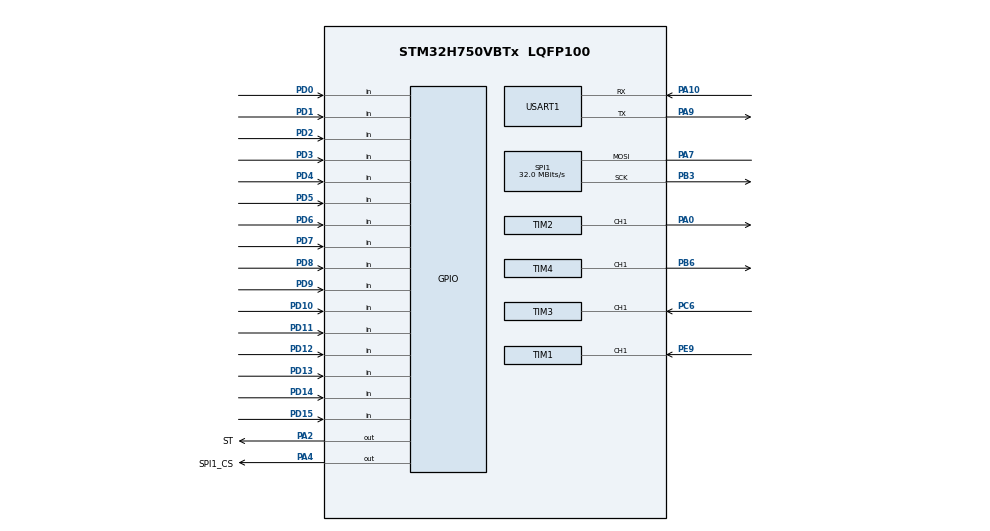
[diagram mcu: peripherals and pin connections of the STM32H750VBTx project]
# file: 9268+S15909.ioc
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CORTEX_M7.CPU_DCache=Disabled
CORTEX_M7.CPU_ICache=Disabled
CORTEX_M7.default_mode_Activation=0
Dma.Request0=USART1_TX
Dma.USART1_TX.0.Direction=DMA_MEMORY_TO_PERIPH
Dma.USART1_TX.0.EventEnable=DISABLE
Dma.USART1_TX.0.FIFOMode=DMA_FIFOMODE_DISABLE
Dma.USART1_TX.0.Instance=DMA1_Stream0
Dma.USART1_TX.0.MemDataAlignment=DMA_MDATAALIGN_BYTE
Dma.USART1_TX.0.MemInc=DMA_MINC_ENABLE
Dma.USART1_TX.0.Mode=DMA_NORMAL
Dma.USART1_TX.0.PeriphDataAlignment=DMA_PDATAALIGN_BYTE
Dma.USART1_TX.0.PeriphInc=DMA_PINC_DISABLE
Dma.USART1_TX.0.Polarity=HAL_DMAMUX_REQ_GEN_RISING
Dma.USART1_TX.0.Priority=DMA_PRIORITY_MEDIUM
Dma.USART1_TX.0.RequestNumber=1
Dma.USART1_TX.0.SignalID=NONE
Dma.USART1_TX.0.SyncEnable=DISABLE
Dma.USART1_TX.0.SyncPolarity=HAL_DMAMUX_SYNC_NO_EVENT
Dma.USART1_TX.0.SyncRequestNumber=1
Dma.USART1_TX.0.SyncSignalID=NONE
Mcu.Family=STM32H7
Mcu.Name=STM32H750VBTx
Mcu.Package=LQFP100
NVIC.DMA1_Stream0_IRQn=true\:0\:0\:false\:false\:true\:false\:true\:true
NVIC.PriorityGroup=NVIC_PRIORITYGROUP_4
NVIC.TIM1_CC_IRQn=true\:0\:0\:false\:false\:true\:true\:true\:true
NVIC.TIM1_TRG_COM_IRQn=true\:0\:0\:false\:false\:true\:true\:true\:true
NVIC.TIM3_IRQn=true\:0\:0\:false\:false\:true\:true\:true\:true
NVIC.USART1_IRQn=true\:0\:0\:false\:false\:true\:true\:true\:true
PA0.Signal=S_TIM2_CH1_ETR
PA10.GPIO_Speed=GPIO_SPEED_FREQ_HIGH
PA10.Mode=Asynchronous
PA10.Signal=USART1_RX
PA2.GPIO_Label=ST
PA2.GPIO_Speed=GPIO_SPEED_FREQ_HIGH
PA2.Signal=GPIO_Output
PA4.GPIO_Label=SPI1_CS
PA4.GPIO_Speed=GPIO_SPEED_FREQ_VERY_HIGH
PA4.Signal=GPIO_Output
PA7.Mode=Simplex_Bidirectional_Master
PA7.Signal=SPI1_MOSI
PA9.GPIO_Speed=GPIO_SPEED_FREQ_HIGH
PA9.Mode=Asynchronous
PA9.Signal=USART1_TX
PB3\ (JTDO/TRACESWO).Mode=Simplex_Bidirectional_Master
PB3\ (JTDO/TRACESWO).Signal=SPI1_SCK
PB6.Signal=S_TIM4_CH1
PC6.Signal=S_TIM3_CH1
PD0.Signal=GPIO_Input
PD1.Signal=GPIO_Input
PD10.Signal=GPIO_Input
PD11.Signal=GPIO_Input
PD12.Signal=GPIO_Input
PD13.Signal=GPIO_Input
PD14.Signal=GPIO_Input
PD15.Signal=GPIO_Input
PD2.Signal=GPIO_Input
PD3.Signal=GPIO_Input
PD4.Signal=GPIO_Input
PD5.Signal=GPIO_Input
PD6.Signal=GPIO_Input
PD7.Signal=GPIO_Input
PD8.Signal=GPIO_Input
PD9.Signal=GPIO_Input
PE9.Signal=S_TIM1_CH1
PH0-OSC_IN\ (PH0).Mode=HSE-External-Oscillator
PH0-OSC_IN\ (PH0).Signal=RCC_OSC_IN
PH1-OSC_OUT\ (PH1).Mode=HSE-External-Oscillator
PH1-OSC_OUT\ (PH1).Signal=RCC_OSC_OUT
ProjectManager.HeapSize=0x400
ProjectManager.StackSize=0x400
ProjectManager.TargetToolchain=STM32CubeIDE
RCC.ADCFreq_Value=16125000
RCC.APB1Freq_Value=120000000
RCC.APB2Freq_Value=120000000
RCC.APB3Freq_Value=120000000
RCC.APB4Freq_Value=120000000
RCC.CortexFreq_Value=480000000
RCC.D1PPRE=RCC_APB3_DIV2
RCC.D2PPRE1=RCC_APB1_DIV2
RCC.D2PPRE2=RCC_APB2_DIV2
RCC.D3PPRE=RCC_APB4_DIV2
RCC.DIVM1=2
RCC.DIVN1=240
RCC.HCLKFreq_Value=240000000
RCC.HPRE=RCC_HCLK_DIV2
RCC.HSE_VALUE=8000000
RCC.PLLSourceVirtual=RCC_PLLSOURCE_HSE
RCC.PWR_Regulator_Voltage_Scale=PWR_REGULATOR_VOLTAGE_SCALE0
RCC.ProductRev=revV
RCC.SPI123CLockSelection=RCC_SPI123CLKSOURCE_CLKP
RCC.SYSCLKFreq_VALUE=480000000
RCC.SYSCLKSource=RCC_SYSCLKSOURCE_PLLCLK
RCC.USBFreq_Value=480000000
SH.S_TIM1_CH1.0=TIM1_CH1,TriggerSource_TI1FP1
SH.S_TIM1_CH1.1=TIM1_CH1,Input_Capture1_from_TI1
SH.S_TIM2_CH1_ETR.0=TIM2_CH1,PWM Generation1 CH1
SH.S_TIM3_CH1.0=TIM3_CH1,Input_Capture1_from_TI1
SH.S_TIM3_CH1.1=TIM3_CH1,TriggerSource_TI1FP1
SH.S_TIM4_CH1.0=TIM4_CH1,PWM Generation1 CH1
SPI1.BaudRatePrescaler=SPI_BAUDRATEPRESCALER_2
SPI1.CalculateBaudRate=32.0 MBits/s
SPI1.DataSize=SPI_DATASIZE_8BIT
SPI1.Direction=SPI_DIRECTION_1LINE
SPI1.Mode=SPI_MODE_MASTER
SPI1.VirtualType=VM_MASTER
TIM1.Channel-Input_Capture1_from_TI1=TIM_CHANNEL_1
TIM1.Prescaler=24-1
TIM2.Channel-PWM\ Generation1\ CH1=TIM_CHANNEL_1
TIM2.Period=100-1
TIM2.Prescaler=10-1
TIM2.Pulse-PWM\ Generation1\ CH1=50
TIM3.Channel-Input_Capture1_from_TI1=TIM_CHANNEL_1
TIM3.Prescaler=10-1
TIM4.Channel-PWM\ Generation1\ CH1=TIM_CHANNEL_1
TIM4.Period=2-1
TIM4.Prescaler=3-1
TIM4.Pulse-PWM\ Generation1\ CH1=1
USART1.VirtualMode-Asynchronous=VM_ASYNC
VP_TIM1_VS_ControllerModeReset.Mode=Reset Mode
VP_TIM3_VS_ControllerModeReset.Mode=Reset Mode
board=custom

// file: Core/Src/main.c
/* USER CODE BEGIN Header */
/**
  ******************************************************************************
  * @file           : main.c
  * @brief          : Main program body
  ******************************************************************************
  * @attention
  *
  * Copyright (c) 2024 STMicroelectronics.
  * All rights reserved.
  *
  * This software is licensed under terms that can be found in the LICENSE file
  * in the root directory of this software component.
  * If no LICENSE file comes with this software, it is provided AS-IS.
  *
  ******************************************************************************
  */
/* USER CODE END Header */
#include "main.h"
#include "dma.h"
#include "spi.h"
#include "tim.h"
#include "usart.h"
#include "gpio.h"

/* USER CODE BEGIN Includes */
#include "Retarget.h"
#include "AD9268.h"
#include <string.h>
/* USER CODE END Includes */

void SystemClock_Config(void);
void PeriphCommonClock_Config(void);

int main(void)
{

  /* MCU Configuration--------------------------------------------------------*/

  /* Reset of all peripherals, Initializes the Flash interface and the Systick. */
  HAL_Init();

  /* Configure the system clock */
  SystemClock_Config();

/* Configure the peripherals common clocks */
  PeriphCommonClock_Config();

  /* Initialize all configured peripherals */
  MX_GPIO_Init();
  MX_DMA_Init();
  MX_TIM1_Init();
  MX_TIM2_Init();
  MX_TIM3_Init();
  MX_TIM4_Init();
  MX_SPI1_Init();
  MX_USART1_UART_Init();
  /* USER CODE BEGIN 2 */
    RetargetInit(&huart1);
    HAL_TIM_PWM_Start(&htim2,TIM_CHANNEL_1);
    HAL_TIM_PWM_Start(&htim4,TIM_CHANNEL_1);
    Init_AD9268();
  /* USER CODE END 2 */

  /* Infinite loop */
  while (1)
  {

    /* USER CODE BEGIN 3 */
//    for(int i=0;i<512;i++)
//    {
//        adc_16bit_value[i] = GPIOD->IDR;
//    }
//      memcpy(adc_ans,adc_16bit_value,1024);
//      HAL_UART_Transmit_DMA(&huart1,adc_ans,1024);
      //printf("%d\r\n",adc_16bit_value);
      DMA_Send();
      //printf("h\r\n");

  }
  /* USER CODE END 3 */
}

void SystemClock_Config(void)
{
  RCC_OscInitTypeDef RCC_OscInitStruct = {0};
  RCC_ClkInitTypeDef RCC_ClkInitStruct = {0};

  /** Supply configuration update enable
  */
  HAL_PWREx_ConfigSupply(PWR_LDO_SUPPLY);

  /** Configure the main internal regulator output voltage
  */
  __HAL_PWR_VOLTAGESCALING_CONFIG(PWR_REGULATOR_VOLTAGE_SCALE1);

  while(!__HAL_PWR_GET_FLAG(PWR_FLAG_VOSRDY)) {}

  __HAL_RCC_SYSCFG_CLK_ENABLE();
  __HAL_PWR_VOLTAGESCALING_CONFIG(PWR_REGULATOR_VOLTAGE_SCALE0);

  while(!__HAL_PWR_GET_FLAG(PWR_FLAG_VOSRDY)) {}

  /** Initializes the RCC Oscillators according to the specified parameters
  * in the RCC_OscInitTypeDef structure.
  */
  RCC_OscInitStruct.OscillatorType = RCC_OSCILLATORTYPE_HSI|RCC_OSCILLATORTYPE_HSE;
  RCC_OscInitStruct.HSEState = RCC_HSE_ON;
  RCC_OscInitStruct.HSIState = RCC_HSI_DIV1;
  RCC_OscInitStruct.HSICalibrationValue = RCC_HSICALIBRATION_DEFAULT;
  RCC_OscInitStruct.PLL.PLLState = RCC_PLL_ON;
  RCC_OscInitStruct.PLL.PLLSource = RCC_PLLSOURCE_HSE;
  RCC_OscInitStruct.PLL.PLLM = 2;
  RCC_OscInitStruct.PLL.PLLN = 240;
  RCC_OscInitStruct.PLL.PLLP = 2;
  RCC_OscInitStruct.PLL.PLLQ = 2;
  RCC_OscInitStruct.PLL.PLLR = 2;
  RCC_OscInitStruct.PLL.PLLRGE = RCC_PLL1VCIRANGE_2;
  RCC_OscInitStruct.PLL.PLLVCOSEL = RCC_PLL1VCOWIDE;
  RCC_OscInitStruct.PLL.PLLFRACN = 0;
  if (HAL_RCC_OscConfig(&RCC_OscInitStruct) != HAL_OK)
  {
    Error_Handler();
  }

  /** Initializes the CPU, AHB and APB buses clocks
  */
  RCC_ClkInitStruct.ClockType = RCC_CLOCKTYPE_HCLK|RCC_CLOCKTYPE_SYSCLK
                              |RCC_CLOCKTYPE_PCLK1|RCC_CLOCKTYPE_PCLK2
                              |RCC_CLOCKTYPE_D3PCLK1|RCC_CLOCKTYPE_D1PCLK1;
  RCC_ClkInitStruct.SYSCLKSource = RCC_SYSCLKSOURCE_PLLCLK;
  RCC_ClkInitStruct.SYSCLKDivider = RCC_SYSCLK_DIV1;
  RCC_ClkInitStruct.AHBCLKDivider = RCC_HCLK_DIV2;
  RCC_ClkInitStruct.APB3CLKDivider = RCC_APB3_DIV2;
  RCC_ClkInitStruct.APB1CLKDivider = RCC_APB1_DIV2;
  RCC_ClkInitStruct.APB2CLKDivider = RCC_APB2_DIV2;
  RCC_ClkInitStruct.APB4CLKDivider = RCC_APB4_DIV2;

  if (HAL_RCC_ClockConfig(&RCC_ClkInitStruct, FLASH_LATENCY_4) != HAL_OK)
  {
    Error_Handler();
  }
}

void PeriphCommonClock_Config(void)
{
  RCC_PeriphCLKInitTypeDef PeriphClkInitStruct = {0};

  /** Initializes the peripherals clock
  */
  PeriphClkInitStruct.PeriphClockSelection = RCC_PERIPHCLK_CKPER;
  PeriphClkInitStruct.CkperClockSelection = RCC_CLKPSOURCE_HSI;
  if (HAL_RCCEx_PeriphCLKConfig(&PeriphClkInitStruct) != HAL_OK)
  {
    Error_Handler();
  }
}

void Error_Handler(void)
{
  __disable_irq();
  while (1)
  {
  }
}
